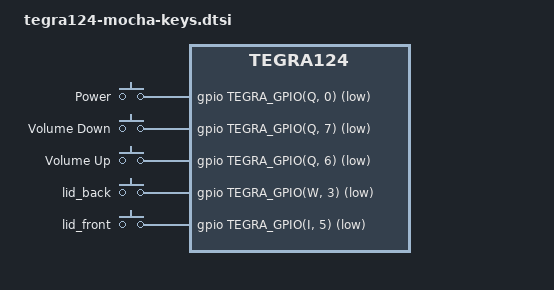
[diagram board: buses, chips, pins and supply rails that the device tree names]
#include <dt-bindings/gpio/tegra-gpio.h>
#include <dt-bindings/input/input.h>

/ {
	gpio-keys {
		compatible = "gpio-keys";
	/*	gpio-keys,name = "gpio-keys";*/
		status = "okay";

		power {
			label = "Power";
			gpios = <&gpio TEGRA_GPIO(Q, 0) GPIO_ACTIVE_LOW>;
			linux,code = <KEY_POWER>;
			wakeup-source;
		};
		
		volume_down {
			label = "Volume Down";
			gpios = <&gpio TEGRA_GPIO(Q, 7) GPIO_ACTIVE_LOW>;
			linux,code = <KEY_VOLUMEDOWN>;
		};

		volume_up {
			label = "Volume Up";
			gpios = <&gpio TEGRA_GPIO(Q, 6) GPIO_ACTIVE_LOW>;
			linux,code = <KEY_VOLUMEUP>;
		};

		hall_intr1 {
			label = "lid_back";
			gpios = <&gpio TEGRA_GPIO(W, 3) GPIO_ACTIVE_LOW>;
			linux,code = <18>;
			linux,input-type = <5>;
			wakeup-source;
		};

		hall_intr2 {
			label = "lid_front";
			gpios = <&gpio TEGRA_GPIO(I, 5) GPIO_ACTIVE_LOW>;
			linux,code = <0>;
			linux,input-type = <5>;
			wakeup-source;
		};
	};
};
